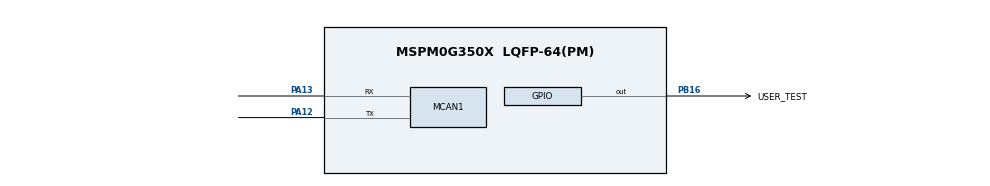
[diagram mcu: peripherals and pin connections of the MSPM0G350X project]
/**
 * @cliArgs --device "MSPM0G350X" --part "Default" --package "LQFP-64(PM)" --product "mspm0_sdk@2.07.00.06"
 * @versions {"tool":"1.25.0+4268"}
 */

/**
 * Import the modules used in this configuration.
 */
const GPIO   = scripting.addModule("/ti/driverlib/GPIO", {}, false);
const GPIO1  = GPIO.addInstance();
const MCAN   = scripting.addModule("/ti/driverlib/MCAN", {}, false);
const MCAN1  = MCAN.addInstance();
const SYSCTL = scripting.addModule("/ti/driverlib/SYSCTL");

/**
 * Write custom configuration values to the imported modules.
 */
const divider4       = system.clockTree["PLL_CLK0_DIV"];
divider4.divideValue = 6;

const divider9       = system.clockTree["UDIV"];
divider9.divideValue = 2;

const mux2       = system.clockTree["CANCLKMUX"];
mux2.inputSelect = "CANCLKMUX_PLLCLK1_OUT";

const mux4       = system.clockTree["EXHFMUX"];
mux4.inputSelect = "EXHFMUX_XTAL";

const mux8       = system.clockTree["HSCLKMUX"];
mux8.inputSelect = "HSCLKMUX_HFCLK";

const mux12       = system.clockTree["SYSPLLMUX"];
mux12.inputSelect = "zSYSPLLMUX_HFCLK";

const pinFunction4        = system.clockTree["HFXT"];
pinFunction4.HFXTStartup  = 10;
pinFunction4.enable       = true;
pinFunction4.inputFreq    = 40;
pinFunction4.HFCLKMonitor = true;

GPIO1.$name                         = "GPIO_LEDS";
GPIO1.port                          = "PORTB";
GPIO1.associatedPins.create(4);
GPIO1.associatedPins[0].$name       = "USER_LED_1";
GPIO1.associatedPins[0].assignedPin = "22";
GPIO1.associatedPins[1].$name       = "USER_LED_2";
GPIO1.associatedPins[1].assignedPin = "26";
GPIO1.associatedPins[2].$name       = "USER_LED_3";
GPIO1.associatedPins[2].assignedPin = "27";
GPIO1.associatedPins[3].$name       = "USER_TEST";
GPIO1.associatedPins[3].pin.$assign = "PB16";

const Board = scripting.addModule("/ti/driverlib/Board", {}, false);

MCAN1.$name                    = "MCAN0";
MCAN1.wkupReqEnable            = true;
MCAN1.autoWkupEnable           = true;
MCAN1.emulationEnable          = true;
MCAN1.tdcEnable                = true;
MCAN1.additionalCoreConfig     = true;
MCAN1.rrfs                     = true;
MCAN1.txEventFIFOWaterMark     = 0;
MCAN1.rxFIFO0waterMark         = 0;
MCAN1.stdFiltID1               = 4;
MCAN1.enableInterrupt          = true;
MCAN1.interruptLine            = ["DL_MCAN_INTR_LINE_NUM_1"];
MCAN1.m0interrupts             = ["DL_MCAN_MSP_INTERRUPT_LINE1"];
MCAN1.overrideRetention        = true;
MCAN1.fdMode                   = false;
MCAN1.desiredNomRate           = 125;
MCAN1.anfs                     = "2";
MCAN1.anfe                     = "1";
MCAN1.rrfe                     = true;
MCAN1.interruptFlags           = ["DL_MCAN_INTERRUPT_ARA","DL_MCAN_INTERRUPT_BEU","DL_MCAN_INTERRUPT_BO","DL_MCAN_INTERRUPT_DRX","DL_MCAN_INTERRUPT_ELO","DL_MCAN_INTERRUPT_EP","DL_MCAN_INTERRUPT_EW","DL_MCAN_INTERRUPT_MRAF","DL_MCAN_INTERRUPT_PEA","DL_MCAN_INTERRUPT_PED","DL_MCAN_INTERRUPT_RF0N","DL_MCAN_INTERRUPT_RF1N","DL_MCAN_INTERRUPT_TC","DL_MCAN_INTERRUPT_TOO","DL_MCAN_INTERRUPT_TSW","DL_MCAN_INTERRUPT_WDI"];
MCAN1.interruptLine1Flag       = ["DL_MCAN_INTERRUPT_DRX","DL_MCAN_INTERRUPT_RF0N","DL_MCAN_INTERRUPT_RF1N","DL_MCAN_INTERRUPT_TC"];
MCAN1.lss                      = 0;
MCAN1.txBufElemSize            = "DL_MCAN_ELEM_SIZE_8BYTES";
MCAN1.rxBufElemSize            = "DL_MCAN_ELEM_SIZE_8BYTES";
MCAN1.rxFIFO0ElemSize          = "DL_MCAN_ELEM_SIZE_8BYTES";
MCAN1.rxFIFO1ElemSize          = "DL_MCAN_ELEM_SIZE_8BYTES";
MCAN1.rxFIFO0size              = 0;
MCAN1.extFiltElem              = "010";
MCAN1.rxFIFO1size              = 16;
MCAN1.rxFIFO1waterMark         = 8;
MCAN1.peripheral.$assign       = "CANFD0";
MCAN1.peripheral.rxPin.$assign = "PA13";
MCAN1.peripheral.txPin.$assign = "PA12";
MCAN1.txPinConfig.$name        = "ti_driverlib_gpio_GPIOPinGeneric0";
MCAN1.rxPinConfig.$name        = "ti_driverlib_gpio_GPIOPinGeneric1";

SYSCTL.clockTreeEn = true;

/**
 * Pinmux solution for unlocked pins/peripherals. This ensures that minor changes to the automatic solver in a future
 * version of the tool will not impact the pinmux you originally saw.  These lines can be completely deleted in order to
 * re-solve from scratch.
 */
pinFunction4.peripheral.$suggestSolution           = "SYSCTL";
pinFunction4.peripheral.hfxInPin.$suggestSolution  = "PA5";
pinFunction4.peripheral.hfxOutPin.$suggestSolution = "PA6";
GPIO1.associatedPins[0].pin.$suggestSolution       = "PB22";
GPIO1.associatedPins[1].pin.$suggestSolution       = "PB26";
GPIO1.associatedPins[2].pin.$suggestSolution       = "PB27";
Board.peripheral.$suggestSolution                  = "DEBUGSS";
Board.peripheral.swclkPin.$suggestSolution         = "PA20";
Board.peripheral.swdioPin.$suggestSolution         = "PA19";
